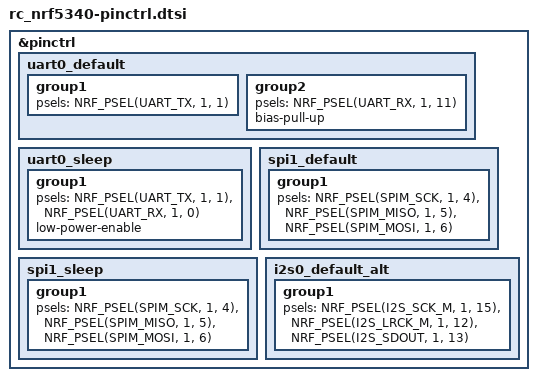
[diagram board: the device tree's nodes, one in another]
&pinctrl {

   /* configuration for uart0 device, default state */
	uart0_default: uart0_default {
		group1 {
			psels = <NRF_PSEL(UART_TX, 1, 1)>;
		};
		group2 {
			psels = <NRF_PSEL(UART_RX, 1, 11)>;
			bias-pull-up;
		};
	};

	uart0_sleep: uart0_sleep {
		group1 {
			psels = <NRF_PSEL(UART_TX, 1, 1)>,
				<NRF_PSEL(UART_RX, 1, 0)>;
			low-power-enable;
		};
	};

 
   spi1_default: spi1_default {                 
        group1{
          psels = <NRF_PSEL(SPIM_SCK, 1, 4)>, <NRF_PSEL(SPIM_MISO, 1, 5)>, <NRF_PSEL(SPIM_MOSI, 1, 6)>;
        };
    };

    spi1_sleep: spi1_sleep {
        group1{
          psels = <NRF_PSEL(SPIM_SCK, 1, 4)>, <NRF_PSEL(SPIM_MISO, 1, 5)>, <NRF_PSEL(SPIM_MOSI, 1, 6)>;
    };
    };

	i2s0_default_alt: i2s0_default_alt {
		group1 {
			psels = <NRF_PSEL(I2S_SCK_M, 1, 15)>,
				<NRF_PSEL(I2S_LRCK_M, 1, 12)>,
				<NRF_PSEL(I2S_SDOUT, 1, 13)>; // Output pin to LED strip
		};
	};

};
